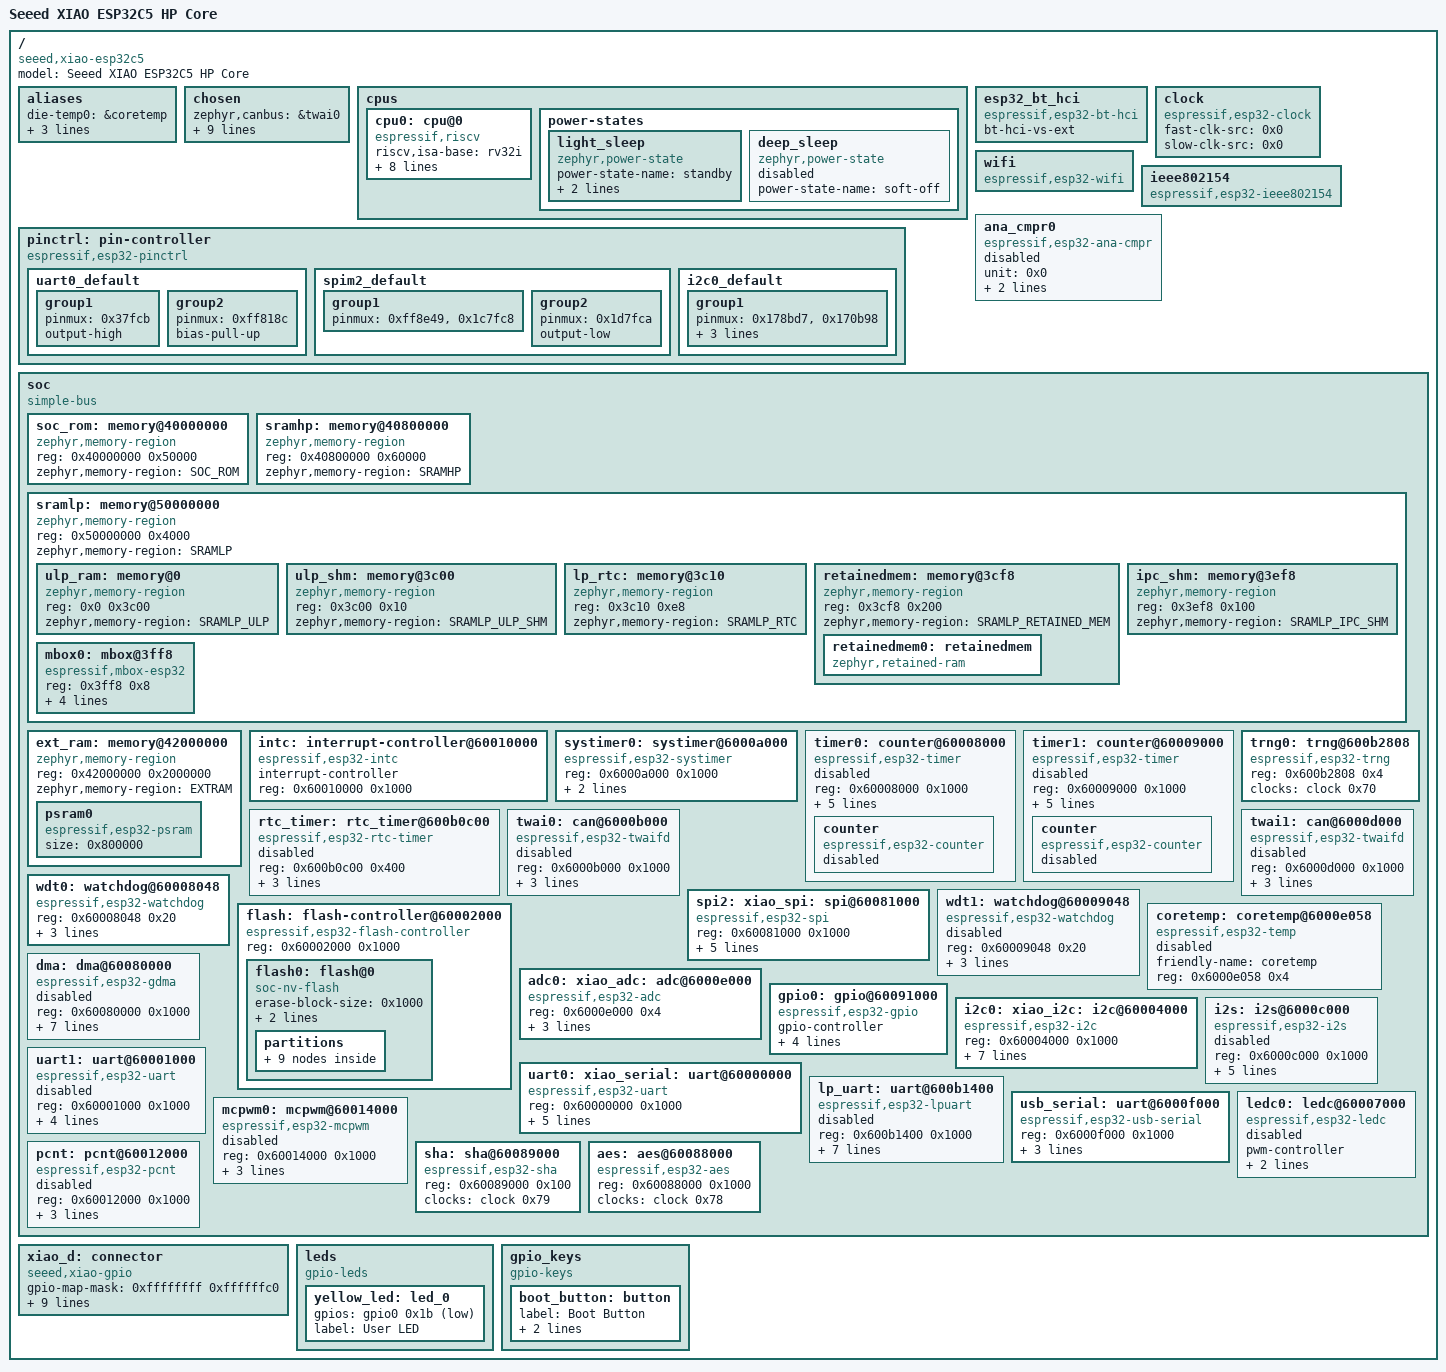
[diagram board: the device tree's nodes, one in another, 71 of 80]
/dts-v1/;

/* node '/' defined in zephyr\dts\riscv\espressif\esp32c5\esp32c5_common.dtsi:16 */
/ {
	#address-cells = < 0x1 >;             /* in zephyr\dts\riscv\espressif\esp32c5\esp32c5_common.dtsi:17 */
	#size-cells = < 0x1 >;                /* in zephyr\dts\riscv\espressif\esp32c5\esp32c5_common.dtsi:18 */
	model = "Seeed XIAO ESP32C5 HP Core"; /* in zephyr\boards\seeed\xiao_esp32c5\xiao_esp32c5_hpcore.dts:15 */
	compatible = "seeed,xiao-esp32c5";    /* in zephyr\boards\seeed\xiao_esp32c5\xiao_esp32c5_hpcore.dts:16 */

	/* node '/aliases' defined in zephyr\dts\riscv\espressif\esp32c5\esp32c5_common.dtsi:20 */
	aliases {
		die-temp0 = &coretemp;             /* in zephyr\dts\riscv\espressif\esp32c5\esp32c5_common.dtsi:21 */
		retainedmemdevice = &retainedmem0; /* in zephyr\dts\riscv\espressif\esp32c5\esp32c5_common.dtsi:22 */
		led0 = &yellow_led;                /* in zephyr\boards\seeed\xiao_esp32c5\xiao_esp32c5_hpcore.dts:37 */
		watchdog0 = &wdt0;                 /* in zephyr\boards\seeed\xiao_esp32c5\xiao_esp32c5_hpcore.dts:38 */
	};

	/* node '/chosen' defined in zephyr\dts\riscv\espressif\esp32c5\esp32c5_common.dtsi:25 */
	chosen {
		zephyr,canbus = &twai0;                   /* in zephyr\dts\riscv\espressif\esp32c5\esp32c5_common.dtsi:26 */
		zephyr,entropy = &trng0;                  /* in zephyr\dts\riscv\espressif\esp32c5\esp32c5_common.dtsi:27 */
		zephyr,flash-controller = &flash;         /* in zephyr\dts\riscv\espressif\esp32c5\esp32c5_common.dtsi:28 */
		zephyr,bt-hci = &esp32_bt_hci;            /* in zephyr\dts\riscv\espressif\esp32c5\esp32c5_common.dtsi:29 */
		zephyr,sram = &sramhp;                    /* in zephyr\boards\seeed\xiao_esp32c5\xiao_esp32c5_hpcore.dts:19 */
		zephyr,console = &usb_serial;             /* in zephyr\boards\seeed\xiao_esp32c5\xiao_esp32c5_hpcore.dts:20 */
		zephyr,shell-uart = &usb_serial;          /* in zephyr\boards\seeed\xiao_esp32c5\xiao_esp32c5_hpcore.dts:21 */
		zephyr,flash = &flash0;                   /* in zephyr\boards\seeed\xiao_esp32c5\xiao_esp32c5_hpcore.dts:22 */
		zephyr,code-partition = &slot0_partition; /* in zephyr\boards\seeed\xiao_esp32c5\xiao_esp32c5_hpcore.dts:23 */
		zephyr,ieee802154 = &ieee802154;          /* in zephyr\boards\seeed\xiao_esp32c5\xiao_esp32c5_hpcore.dts:24 */
	};

	/* node '/cpus' defined in zephyr\dts\riscv\espressif\esp32c5\esp32c5_common.dtsi:32 */
	cpus {
		#address-cells = < 0x1 >; /* in zephyr\dts\riscv\espressif\esp32c5\esp32c5_common.dtsi:33 */
		#size-cells = < 0x0 >;    /* in zephyr\dts\riscv\espressif\esp32c5\esp32c5_common.dtsi:34 */

		/* node '/cpus/cpu@0' defined in zephyr\dts\riscv\espressif\esp32c5\esp32c5_common.dtsi:36 */
		cpu0: cpu@0 {
			device_type = "cpu";                             /* in zephyr\dts\riscv\espressif\esp32c5\esp32c5_common.dtsi:37 */
			compatible = "espressif,riscv",
			             "riscv";                            /* in zephyr\dts\riscv\espressif\esp32c5\esp32c5_common.dtsi:38 */
			riscv,isa-base = "rv32i";                        /* in zephyr\dts\riscv\espressif\esp32c5\esp32c5_common.dtsi:39 */
			riscv,isa-extensions = "i",
			                       "m",
			                       "a",
			                       "c",
			                       "zicsr",
			                       "zifencei";               /* in zephyr\dts\riscv\espressif\esp32c5\esp32c5_common.dtsi:40 */
			reg = < 0x0 >;                                   /* in zephyr\dts\riscv\espressif\esp32c5\esp32c5_common.dtsi:41 */
			cpu-power-states = < &light_sleep &deep_sleep >; /* in zephyr\dts\riscv\espressif\esp32c5\esp32c5_common.dtsi:42 */
			clock-source = < 0x1 >;                          /* in zephyr\dts\riscv\espressif\esp32c5\esp32c5_common.dtsi:43 */
			clock-frequency = < 0xe4e1c00 >;                 /* in zephyr\dts\riscv\espressif\esp32c5\esp32c5_common.dtsi:44 */
			xtal-freq = < 0x2dc6c00 >;                       /* in zephyr\dts\riscv\espressif\esp32c5\esp32c5_common.dtsi:45 */
			d-cache-line-size = < 0x20 >;                    /* in zephyr\dts\riscv\espressif\esp32c5\esp32c5_common.dtsi:46 */
		};

		/* node '/cpus/power-states' defined in zephyr\dts\riscv\espressif\esp32c5\esp32c5_common.dtsi:49 */
		power-states {

			/* node '/cpus/power-states/light_sleep' defined in zephyr\dts\riscv\espressif\esp32c5\esp32c5_common.dtsi:50 */
			light_sleep: light_sleep {
				compatible = "zephyr,power-state"; /* in zephyr\dts\riscv\espressif\esp32c5\esp32c5_common.dtsi:51 */
				power-state-name = "standby";      /* in zephyr\dts\riscv\espressif\esp32c5\esp32c5_common.dtsi:52 */
				min-residency-us = < 0x9c4 >;      /* in zephyr\dts\riscv\espressif\esp32c5\esp32c5_common.dtsi:53 */
				exit-latency-us = < 0x32 >;        /* in zephyr\dts\riscv\espressif\esp32c5\esp32c5_common.dtsi:54 */
				phandle = < 0x1 >;                 /* in zephyr\dts\riscv\espressif\esp32c5\esp32c5_common.dtsi:42 */
			};

			/* node '/cpus/power-states/deep_sleep' defined in zephyr\dts\riscv\espressif\esp32c5\esp32c5_common.dtsi:57 */
			deep_sleep: deep_sleep {
				compatible = "zephyr,power-state"; /* in zephyr\dts\riscv\espressif\esp32c5\esp32c5_common.dtsi:61 */
				power-state-name = "soft-off";     /* in zephyr\dts\riscv\espressif\esp32c5\esp32c5_common.dtsi:62 */
				status = "disabled";               /* in zephyr\dts\riscv\espressif\esp32c5\esp32c5_common.dtsi:63 */
				phandle = < 0x2 >;                 /* in zephyr\dts\riscv\espressif\esp32c5\esp32c5_common.dtsi:42 */
			};
		};
	};

	/* node '/pin-controller' defined in zephyr\dts\riscv\espressif\esp32c5\esp32c5_common.dtsi:68 */
	pinctrl: pin-controller {
		compatible = "espressif,esp32-pinctrl"; /* in zephyr\dts\riscv\espressif\esp32c5\esp32c5_common.dtsi:69 */
		status = "okay";                        /* in zephyr\dts\riscv\espressif\esp32c5\esp32c5_common.dtsi:70 */

		/* node '/pin-controller/uart0_default' defined in zephyr\boards\seeed\xiao_esp32c5\xiao_esp32c5-pinctrl.dtsi:9 */
		uart0_default: uart0_default {
			phandle = < 0xa >; /* in zephyr\boards\seeed\xiao_esp32c5\xiao_esp32c5_hpcore.dts:92 */

			/* node '/pin-controller/uart0_default/group1' defined in zephyr\boards\seeed\xiao_esp32c5\xiao_esp32c5-pinctrl.dtsi:10 */
			group1 {
				pinmux = < 0x37fcb >; /* in zephyr\boards\seeed\xiao_esp32c5\xiao_esp32c5-pinctrl.dtsi:11 */
				output-high;          /* in zephyr\boards\seeed\xiao_esp32c5\xiao_esp32c5-pinctrl.dtsi:12 */
			};

			/* node '/pin-controller/uart0_default/group2' defined in zephyr\boards\seeed\xiao_esp32c5\xiao_esp32c5-pinctrl.dtsi:15 */
			group2 {
				pinmux = < 0xff818c >; /* in zephyr\boards\seeed\xiao_esp32c5\xiao_esp32c5-pinctrl.dtsi:16 */
				bias-pull-up;          /* in zephyr\boards\seeed\xiao_esp32c5\xiao_esp32c5-pinctrl.dtsi:17 */
			};
		};

		/* node '/pin-controller/spim2_default' defined in zephyr\boards\seeed\xiao_esp32c5\xiao_esp32c5-pinctrl.dtsi:21 */
		spim2_default: spim2_default {
			phandle = < 0x6 >; /* in zephyr\boards\seeed\xiao_esp32c5\xiao_esp32c5_hpcore.dts:85 */

			/* node '/pin-controller/spim2_default/group1' defined in zephyr\boards\seeed\xiao_esp32c5\xiao_esp32c5-pinctrl.dtsi:22 */
			group1 {
				pinmux = < 0xff8e49 >,
				         < 0x1c7fc8 >; /* in zephyr\boards\seeed\xiao_esp32c5\xiao_esp32c5-pinctrl.dtsi:23 */
			};

			/* node '/pin-controller/spim2_default/group2' defined in zephyr\boards\seeed\xiao_esp32c5\xiao_esp32c5-pinctrl.dtsi:27 */
			group2 {
				pinmux = < 0x1d7fca >; /* in zephyr\boards\seeed\xiao_esp32c5\xiao_esp32c5-pinctrl.dtsi:28 */
				output-low;            /* in zephyr\boards\seeed\xiao_esp32c5\xiao_esp32c5-pinctrl.dtsi:29 */
			};
		};

		/* node '/pin-controller/i2c0_default' defined in zephyr\boards\seeed\xiao_esp32c5\xiao_esp32c5-pinctrl.dtsi:33 */
		i2c0_default: i2c0_default {
			phandle = < 0x8 >; /* in zephyr\boards\seeed\xiao_esp32c5\xiao_esp32c5_hpcore.dts:77 */

			/* node '/pin-controller/i2c0_default/group1' defined in zephyr\boards\seeed\xiao_esp32c5\xiao_esp32c5-pinctrl.dtsi:34 */
			group1 {
				pinmux = < 0x178bd7 >,
				         < 0x170b98 >; /* in zephyr\boards\seeed\xiao_esp32c5\xiao_esp32c5-pinctrl.dtsi:35 */
				bias-pull-up;          /* in zephyr\boards\seeed\xiao_esp32c5\xiao_esp32c5-pinctrl.dtsi:37 */
				drive-open-drain;      /* in zephyr\boards\seeed\xiao_esp32c5\xiao_esp32c5-pinctrl.dtsi:38 */
				output-high;           /* in zephyr\boards\seeed\xiao_esp32c5\xiao_esp32c5-pinctrl.dtsi:39 */
			};
		};
	};

	/* node '/esp32_bt_hci' defined in zephyr\dts\riscv\espressif\esp32c5\esp32c5_common.dtsi:73 */
	esp32_bt_hci: esp32_bt_hci {
		compatible = "espressif,esp32-bt-hci"; /* in zephyr\dts\riscv\espressif\esp32c5\esp32c5_common.dtsi:74 */
		bt-hci-vs-ext;                         /* in zephyr\dts\riscv\espressif\esp32c5\esp32c5_common.dtsi:75 */
		status = "okay";                       /* in zephyr\boards\seeed\xiao_esp32c5\xiao_esp32c5_hpcore.dts:105 */
	};

	/* node '/clock' defined in zephyr\dts\riscv\espressif\esp32c5\esp32c5_common.dtsi:79 */
	clock: clock {
		compatible = "espressif,esp32-clock"; /* in zephyr\dts\riscv\espressif\esp32c5\esp32c5_common.dtsi:80 */
		fast-clk-src = < 0x0 >;               /* in zephyr\dts\riscv\espressif\esp32c5\esp32c5_common.dtsi:81 */
		slow-clk-src = < 0x0 >;               /* in zephyr\dts\riscv\espressif\esp32c5\esp32c5_common.dtsi:82 */
		#clock-cells = < 0x1 >;               /* in zephyr\dts\riscv\espressif\esp32c5\esp32c5_common.dtsi:83 */
		status = "okay";                      /* in zephyr\dts\riscv\espressif\esp32c5\esp32c5_common.dtsi:84 */
		phandle = < 0x5 >;                    /* in zephyr\dts\riscv\espressif\esp32c5\esp32c5_common.dtsi:222 */
	};

	/* node '/wifi' defined in zephyr\dts\riscv\espressif\esp32c5\esp32c5_common.dtsi:87 */
	wifi: wifi {
		compatible = "espressif,esp32-wifi"; /* in zephyr\dts\riscv\espressif\esp32c5\esp32c5_common.dtsi:88 */
		status = "okay";                     /* in zephyr\boards\seeed\xiao_esp32c5\xiao_esp32c5_hpcore.dts:97 */
	};

	/* node '/ieee802154' defined in zephyr\dts\riscv\espressif\esp32c5\esp32c5_common.dtsi:92 */
	ieee802154: ieee802154 {
		compatible = "espressif,esp32-ieee802154"; /* in zephyr\dts\riscv\espressif\esp32c5\esp32c5_common.dtsi:93 */
		status = "okay";                           /* in zephyr\boards\seeed\xiao_esp32c5\xiao_esp32c5_hpcore.dts:101 */
	};

	/* node '/ana_cmpr0' defined in zephyr\dts\riscv\espressif\esp32c5\esp32c5_common.dtsi:97 */
	ana_cmpr0: ana_cmpr0 {
		compatible = "espressif,esp32-ana-cmpr"; /* in zephyr\dts\riscv\espressif\esp32c5\esp32c5_common.dtsi:98 */
		unit = < 0x0 >;                          /* in zephyr\dts\riscv\espressif\esp32c5\esp32c5_common.dtsi:99 */
		interrupts = < 0x20 0x0 0x0 >;           /* in zephyr\dts\riscv\espressif\esp32c5\esp32c5_common.dtsi:100 */
		interrupt-parent = < &intc >;            /* in zephyr\dts\riscv\espressif\esp32c5\esp32c5_common.dtsi:101 */
		status = "disabled";                     /* in zephyr\dts\riscv\espressif\esp32c5\esp32c5_common.dtsi:102 */
	};

	/* node '/soc' defined in zephyr\dts\riscv\espressif\esp32c5\esp32c5_common.dtsi:105 */
	soc {
		#address-cells = < 0x1 >;  /* in zephyr\dts\riscv\espressif\esp32c5\esp32c5_common.dtsi:106 */
		#size-cells = < 0x1 >;     /* in zephyr\dts\riscv\espressif\esp32c5\esp32c5_common.dtsi:107 */
		compatible = "simple-bus"; /* in zephyr\dts\riscv\espressif\esp32c5\esp32c5_common.dtsi:108 */
		ranges;                    /* in zephyr\dts\riscv\espressif\esp32c5\esp32c5_common.dtsi:109 */

		/* node '/soc/memory@40000000' defined in zephyr\dts\riscv\espressif\esp32c5\esp32c5_common.dtsi:116 */
		soc_rom: memory@40000000 {
			compatible = "zephyr,memory-region"; /* in zephyr\dts\riscv\espressif\esp32c5\esp32c5_common.dtsi:117 */
			reg = < 0x40000000 0x50000 >;        /* in zephyr\dts\riscv\espressif\esp32c5\esp32c5_common.dtsi:118 */
			zephyr,memory-region = "SOC_ROM";    /* in zephyr\dts\riscv\espressif\esp32c5\esp32c5_common.dtsi:119 */
		};

		/* node '/soc/memory@40800000' defined in zephyr\dts\riscv\espressif\esp32c5\esp32c5_common.dtsi:122 */
		sramhp: memory@40800000 {
			compatible = "zephyr,memory-region",
			             "mmio-sram";            /* in zephyr\dts\riscv\espressif\esp32c5\esp32c5_common.dtsi:123 */
			reg = < 0x40800000 0x60000 >;        /* in zephyr\dts\riscv\espressif\esp32c5\esp32c5_common.dtsi:124 */
			zephyr,memory-region = "SRAMHP";     /* in zephyr\dts\riscv\espressif\esp32c5\esp32c5_common.dtsi:125 */
		};

		/* node '/soc/memory@50000000' defined in zephyr\dts\riscv\espressif\esp32c5\esp32c5_common.dtsi:128 */
		sramlp: memory@50000000 {
			#address-cells = < 0x1 >;            /* in zephyr\dts\riscv\espressif\esp32c5\esp32c5_common.dtsi:129 */
			#size-cells = < 0x1 >;               /* in zephyr\dts\riscv\espressif\esp32c5\esp32c5_common.dtsi:130 */
			compatible = "zephyr,memory-region",
			             "mmio-sram";            /* in zephyr\dts\riscv\espressif\esp32c5\esp32c5_common.dtsi:131 */
			reg = < 0x50000000 0x4000 >;         /* in zephyr\dts\riscv\espressif\esp32c5\esp32c5_common.dtsi:132 */
			zephyr,memory-region = "SRAMLP";     /* in zephyr\dts\riscv\espressif\esp32c5\esp32c5_common.dtsi:133 */
			ranges = < 0x0 0x50000000 0x4000 >;  /* in zephyr\dts\riscv\espressif\esp32c5\esp32c5_common.dtsi:134 */

			/* node '/soc/memory@50000000/memory@0' defined in zephyr\dts\riscv\espressif\esp32c5\esp32c5_common.dtsi:136 */
			ulp_ram: memory@0 {
				compatible = "zephyr,memory-region",
				             "mmio-sram";            /* in zephyr\dts\riscv\espressif\esp32c5\esp32c5_common.dtsi:137 */
				reg = < 0x0 0x3c00 >;                /* in zephyr\dts\riscv\espressif\esp32c5\esp32c5_common.dtsi:138 */
				zephyr,memory-region = "SRAMLP_ULP"; /* in zephyr\dts\riscv\espressif\esp32c5\esp32c5_common.dtsi:139 */
			};

			/* node '/soc/memory@50000000/memory@3c00' defined in zephyr\dts\riscv\espressif\esp32c5\esp32c5_common.dtsi:142 */
			ulp_shm: memory@3c00 {
				compatible = "zephyr,memory-region",
				             "mmio-sram";                /* in zephyr\dts\riscv\espressif\esp32c5\esp32c5_common.dtsi:143 */
				reg = < 0x3c00 0x10 >;                   /* in zephyr\dts\riscv\espressif\esp32c5\esp32c5_common.dtsi:144 */
				zephyr,memory-region = "SRAMLP_ULP_SHM"; /* in zephyr\dts\riscv\espressif\esp32c5\esp32c5_common.dtsi:145 */
			};

			/* node '/soc/memory@50000000/memory@3c10' defined in zephyr\dts\riscv\espressif\esp32c5\esp32c5_common.dtsi:148 */
			lp_rtc: memory@3c10 {
				compatible = "zephyr,memory-region",
				             "mmio-sram";            /* in zephyr\dts\riscv\espressif\esp32c5\esp32c5_common.dtsi:149 */
				reg = < 0x3c10 0xe8 >;               /* in zephyr\dts\riscv\espressif\esp32c5\esp32c5_common.dtsi:150 */
				zephyr,memory-region = "SRAMLP_RTC"; /* in zephyr\dts\riscv\espressif\esp32c5\esp32c5_common.dtsi:151 */
			};

			/* node '/soc/memory@50000000/memory@3cf8' defined in zephyr\dts\riscv\espressif\esp32c5\esp32c5_common.dtsi:154 */
			retainedmem: memory@3cf8 {
				compatible = "zephyr,memory-region",
				             "mmio-sram";                     /* in zephyr\dts\riscv\espressif\esp32c5\esp32c5_common.dtsi:155 */
				reg = < 0x3cf8 0x200 >;                       /* in zephyr\dts\riscv\espressif\esp32c5\esp32c5_common.dtsi:156 */
				ranges = < 0x0 0x3cf8 0x200 >;                /* in zephyr\dts\riscv\espressif\esp32c5\esp32c5_common.dtsi:157 */
				zephyr,memory-region = "SRAMLP_RETAINED_MEM"; /* in zephyr\dts\riscv\espressif\esp32c5\esp32c5_common.dtsi:158 */
				status = "okay";                              /* in zephyr\dts\riscv\espressif\esp32c5\esp32c5_common.dtsi:159 */
				#address-cells = < 0x1 >;                     /* in zephyr\dts\riscv\espressif\esp32c5\esp32c5_common.dtsi:160 */
				#size-cells = < 0x1 >;                        /* in zephyr\dts\riscv\espressif\esp32c5\esp32c5_common.dtsi:161 */

				/* node '/soc/memory@50000000/memory@3cf8/retainedmem' defined in zephyr\dts\riscv\espressif\esp32c5\esp32c5_common.dtsi:163 */
				retainedmem0: retainedmem {
					compatible = "zephyr,retained-ram"; /* in zephyr\dts\riscv\espressif\esp32c5\esp32c5_common.dtsi:164 */
					status = "okay";                    /* in zephyr\dts\riscv\espressif\esp32c5\esp32c5_common.dtsi:165 */
					ranges;                             /* in zephyr\dts\riscv\espressif\esp32c5\esp32c5_common.dtsi:166 */
					#address-cells = < 0x1 >;           /* in zephyr\dts\riscv\espressif\esp32c5\esp32c5_common.dtsi:167 */
					#size-cells = < 0x1 >;              /* in zephyr\dts\riscv\espressif\esp32c5\esp32c5_common.dtsi:168 */
				};
			};

			/* node '/soc/memory@50000000/memory@3ef8' defined in zephyr\dts\riscv\espressif\esp32c5\esp32c5_common.dtsi:172 */
			ipc_shm: memory@3ef8 {
				compatible = "zephyr,memory-region",
				             "mmio-sram";                /* in zephyr\dts\riscv\espressif\esp32c5\esp32c5_common.dtsi:173 */
				reg = < 0x3ef8 0x100 >;                  /* in zephyr\dts\riscv\espressif\esp32c5\esp32c5_common.dtsi:174 */
				zephyr,memory-region = "SRAMLP_IPC_SHM"; /* in zephyr\dts\riscv\espressif\esp32c5\esp32c5_common.dtsi:175 */
				phandle = < 0x4 >;                       /* in zephyr\dts\riscv\espressif\esp32c5\esp32c5_common.dtsi:182 */
			};

			/* node '/soc/memory@50000000/mbox@3ff8' defined in zephyr\dts\riscv\espressif\esp32c5\esp32c5_common.dtsi:178 */
			mbox0: mbox@3ff8 {
				compatible = "espressif,mbox-esp32"; /* in zephyr\dts\riscv\espressif\esp32c5\esp32c5_common.dtsi:179 */
				reg = < 0x3ff8 0x8 >;                /* in zephyr\dts\riscv\espressif\esp32c5\esp32c5_common.dtsi:180 */
				status = "okay";                     /* in zephyr\dts\riscv\espressif\esp32c5\esp32c5_common.dtsi:181 */
				shared-memory = < &ipc_shm >;        /* in zephyr\dts\riscv\espressif\esp32c5\esp32c5_common.dtsi:182 */
				shared-memory-size = < 0x100 >;      /* in zephyr\dts\riscv\espressif\esp32c5\esp32c5_common.dtsi:183 */
				interrupts = < 0xd 0x0 0x0 >,
				             < 0x5 0x0 0x0 >;        /* in zephyr\dts\riscv\espressif\esp32c5\esp32c5_common.dtsi:184 */
				interrupt-parent = < &intc >;        /* in zephyr\dts\riscv\espressif\esp32c5\esp32c5_common.dtsi:186 */
				#mbox-cells = < 0x1 >;               /* in zephyr\dts\riscv\espressif\esp32c5\esp32c5_common.dtsi:187 */
			};
		};

		/* node '/soc/memory@42000000' defined in zephyr\dts\riscv\espressif\esp32c5\esp32c5_common.dtsi:191 */
		ext_ram: memory@42000000 {
			compatible = "zephyr,memory-region"; /* in zephyr\dts\riscv\espressif\esp32c5\esp32c5_common.dtsi:192 */
			reg = < 0x42000000 0x2000000 >;      /* in zephyr\dts\riscv\espressif\esp32c5\esp32c5_common.dtsi:193 */
			zephyr,memory-region = "EXTRAM";     /* in zephyr\dts\riscv\espressif\esp32c5\esp32c5_common.dtsi:194 */

			/* node '/soc/memory@42000000/psram0' defined in zephyr\dts\riscv\espressif\esp32c5\esp32c5_common.dtsi:196 */
			psram0: psram0 {
				compatible = "espressif,esp32-psram"; /* in zephyr\dts\riscv\espressif\esp32c5\esp32c5_common.dtsi:197 */
				size = < 0x800000 >;                  /* in zephyr\dts\riscv\espressif\esp32c5\esp32c5_wroom_n8r8.dtsi:17 */
			};
		};

		/* node '/soc/interrupt-controller@60010000' defined in zephyr\dts\riscv\espressif\esp32c5\esp32c5_common.dtsi:202 */
		intc: interrupt-controller@60010000 {
			compatible = "espressif,esp32-intc"; /* in zephyr\dts\riscv\espressif\esp32c5\esp32c5_common.dtsi:203 */
			#address-cells = < 0x0 >;            /* in zephyr\dts\riscv\espressif\esp32c5\esp32c5_common.dtsi:204 */
			#interrupt-cells = < 0x3 >;          /* in zephyr\dts\riscv\espressif\esp32c5\esp32c5_common.dtsi:205 */
			interrupt-controller;                /* in zephyr\dts\riscv\espressif\esp32c5\esp32c5_common.dtsi:206 */
			reg = < 0x60010000 0x1000 >;         /* in zephyr\dts\riscv\espressif\esp32c5\esp32c5_common.dtsi:207 */
			status = "okay";                     /* in zephyr\dts\riscv\espressif\esp32c5\esp32c5_common.dtsi:208 */
			phandle = < 0x3 >;                   /* in zephyr\dts\riscv\espressif\esp32c5\esp32c5_common.dtsi:101 */
		};

		/* node '/soc/systimer@6000a000' defined in zephyr\dts\riscv\espressif\esp32c5\esp32c5_common.dtsi:211 */
		systimer0: systimer@6000a000 {
			compatible = "espressif,esp32-systimer"; /* in zephyr\dts\riscv\espressif\esp32c5\esp32c5_common.dtsi:212 */
			reg = < 0x6000a000 0x1000 >;             /* in zephyr\dts\riscv\espressif\esp32c5\esp32c5_common.dtsi:213 */
			interrupts = < 0x3d 0x0 0x0 >;           /* in zephyr\dts\riscv\espressif\esp32c5\esp32c5_common.dtsi:214 */
			interrupt-parent = < &intc >;            /* in zephyr\dts\riscv\espressif\esp32c5\esp32c5_common.dtsi:215 */
			status = "okay";                         /* in zephyr\dts\riscv\espressif\esp32c5\esp32c5_common.dtsi:216 */
		};

		/* node '/soc/counter@60008000' defined in zephyr\dts\riscv\espressif\esp32c5\esp32c5_common.dtsi:219 */
		timer0: counter@60008000 {
			compatible = "espressif,esp32-timer"; /* in zephyr\dts\riscv\espressif\esp32c5\esp32c5_common.dtsi:220 */
			reg = < 0x60008000 0x1000 >;          /* in zephyr\dts\riscv\espressif\esp32c5\esp32c5_common.dtsi:221 */
			clocks = < &clock 0x0 >;              /* in zephyr\dts\riscv\espressif\esp32c5\esp32c5_common.dtsi:222 */
			group = < 0x0 >;                      /* in zephyr\dts\riscv\espressif\esp32c5\esp32c5_common.dtsi:223 */
			index = < 0x0 >;                      /* in zephyr\dts\riscv\espressif\esp32c5\esp32c5_common.dtsi:224 */
			interrupts = < 0x39 0x0 0x0 >;        /* in zephyr\dts\riscv\espressif\esp32c5\esp32c5_common.dtsi:225 */
			interrupt-parent = < &intc >;         /* in zephyr\dts\riscv\espressif\esp32c5\esp32c5_common.dtsi:226 */
			status = "disabled";                  /* in zephyr\dts\riscv\espressif\esp32c5\esp32c5_common.dtsi:227 */

			/* node '/soc/counter@60008000/counter' defined in zephyr\dts\riscv\espressif\esp32c5\esp32c5_common.dtsi:229 */
			counter {
				compatible = "espressif,esp32-counter"; /* in zephyr\dts\riscv\espressif\esp32c5\esp32c5_common.dtsi:230 */
				status = "disabled";                    /* in zephyr\dts\riscv\espressif\esp32c5\esp32c5_common.dtsi:231 */
			};
		};

		/* node '/soc/counter@60009000' defined in zephyr\dts\riscv\espressif\esp32c5\esp32c5_common.dtsi:235 */
		timer1: counter@60009000 {
			compatible = "espressif,esp32-timer"; /* in zephyr\dts\riscv\espressif\esp32c5\esp32c5_common.dtsi:236 */
			reg = < 0x60009000 0x1000 >;          /* in zephyr\dts\riscv\espressif\esp32c5\esp32c5_common.dtsi:237 */
			clocks = < &clock 0x1 >;              /* in zephyr\dts\riscv\espressif\esp32c5\esp32c5_common.dtsi:238 */
			group = < 0x1 >;                      /* in zephyr\dts\riscv\espressif\esp32c5\esp32c5_common.dtsi:239 */
			index = < 0x0 >;                      /* in zephyr\dts\riscv\espressif\esp32c5\esp32c5_common.dtsi:240 */
			interrupts = < 0x3b 0x0 0x0 >;        /* in zephyr\dts\riscv\espressif\esp32c5\esp32c5_common.dtsi:241 */
			interrupt-parent = < &intc >;         /* in zephyr\dts\riscv\espressif\esp32c5\esp32c5_common.dtsi:242 */
			status = "disabled";                  /* in zephyr\dts\riscv\espressif\esp32c5\esp32c5_common.dtsi:243 */

			/* node '/soc/counter@60009000/counter' defined in zephyr\dts\riscv\espressif\esp32c5\esp32c5_common.dtsi:245 */
			counter {
				compatible = "espressif,esp32-counter"; /* in zephyr\dts\riscv\espressif\esp32c5\esp32c5_common.dtsi:246 */
				status = "disabled";                    /* in zephyr\dts\riscv\espressif\esp32c5\esp32c5_common.dtsi:247 */
			};
		};

		/* node '/soc/rtc_timer@600b0c00' defined in zephyr\dts\riscv\espressif\esp32c5\esp32c5_common.dtsi:251 */
		rtc_timer: rtc_timer@600b0c00 {
			compatible = "espressif,esp32-rtc-timer"; /* in zephyr\dts\riscv\espressif\esp32c5\esp32c5_common.dtsi:252 */
			reg = < 0x600b0c00 0x400 >;               /* in zephyr\dts\riscv\espressif\esp32c5\esp32c5_common.dtsi:253 */
			clocks = < &clock 0xd >;                  /* in zephyr\dts\riscv\espressif\esp32c5\esp32c5_common.dtsi:254 */
			interrupts = < 0xf 0x0 0x0 >;             /* in zephyr\dts\riscv\espressif\esp32c5\esp32c5_common.dtsi:255 */
			interrupt-parent = < &intc >;             /* in zephyr\dts\riscv\espressif\esp32c5\esp32c5_common.dtsi:256 */
			status = "disabled";                      /* in zephyr\dts\riscv\espressif\esp32c5\esp32c5_common.dtsi:257 */
		};

		/* node '/soc/trng@600b2808' defined in zephyr\dts\riscv\espressif\esp32c5\esp32c5_common.dtsi:260 */
		trng0: trng@600b2808 {
			compatible = "espressif,esp32-trng"; /* in zephyr\dts\riscv\espressif\esp32c5\esp32c5_common.dtsi:261 */
			reg = < 0x600b2808 0x4 >;            /* in zephyr\dts\riscv\espressif\esp32c5\esp32c5_common.dtsi:262 */
			clocks = < &clock 0x70 >;            /* in zephyr\dts\riscv\espressif\esp32c5\esp32c5_common.dtsi:263 */
			status = "okay";                     /* in zephyr\boards\seeed\xiao_esp32c5\xiao_esp32c5_hpcore.dts:53 */
		};

		/* node '/soc/can@6000b000' defined in zephyr\dts\riscv\espressif\esp32c5\esp32c5_common.dtsi:267 */
		twai0: can@6000b000 {
			compatible = "espressif,esp32-twaifd"; /* in zephyr\dts\riscv\espressif\esp32c5\esp32c5_common.dtsi:268 */
			reg = < 0x6000b000 0x1000 >;           /* in zephyr\dts\riscv\espressif\esp32c5\esp32c5_common.dtsi:269 */
			interrupts = < 0x32 0x0 0x0 >;         /* in zephyr\dts\riscv\espressif\esp32c5\esp32c5_common.dtsi:270 */
			interrupt-parent = < &intc >;          /* in zephyr\dts\riscv\espressif\esp32c5\esp32c5_common.dtsi:271 */
			clocks = < &clock 0x6e >;              /* in zephyr\dts\riscv\espressif\esp32c5\esp32c5_common.dtsi:272 */
			status = "disabled";                   /* in zephyr\dts\riscv\espressif\esp32c5\esp32c5_common.dtsi:273 */
		};

		/* node '/soc/can@6000d000' defined in zephyr\dts\riscv\espressif\esp32c5\esp32c5_common.dtsi:276 */
		twai1: can@6000d000 {
			compatible = "espressif,esp32-twaifd"; /* in zephyr\dts\riscv\espressif\esp32c5\esp32c5_common.dtsi:277 */
			reg = < 0x6000d000 0x1000 >;           /* in zephyr\dts\riscv\espressif\esp32c5\esp32c5_common.dtsi:278 */
			interrupts = < 0x34 0x0 0x0 >;         /* in zephyr\dts\riscv\espressif\esp32c5\esp32c5_common.dtsi:279 */
			interrupt-parent = < &intc >;          /* in zephyr\dts\riscv\espressif\esp32c5\esp32c5_common.dtsi:280 */
			clocks = < &clock 0x6f >;              /* in zephyr\dts\riscv\espressif\esp32c5\esp32c5_common.dtsi:281 */
			status = "disabled";                   /* in zephyr\dts\riscv\espressif\esp32c5\esp32c5_common.dtsi:282 */
		};

		/* node '/soc/spi@60081000' defined in zephyr\dts\riscv\espressif\esp32c5\esp32c5_common.dtsi:285 */
		spi2: xiao_spi: spi@60081000 {
			compatible = "espressif,esp32-spi"; /* in zephyr\dts\riscv\espressif\esp32c5\esp32c5_common.dtsi:286 */
			reg = < 0x60081000 0x1000 >;        /* in zephyr\dts\riscv\espressif\esp32c5\esp32c5_common.dtsi:287 */
			interrupts = < 0x4d 0x0 0x0 >;      /* in zephyr\dts\riscv\espressif\esp32c5\esp32c5_common.dtsi:288 */
			interrupt-parent = < &intc >;       /* in zephyr\dts\riscv\espressif\esp32c5\esp32c5_common.dtsi:289 */
			clocks = < &clock 0x6d >;           /* in zephyr\dts\riscv\espressif\esp32c5\esp32c5_common.dtsi:290 */
			dma-host = < 0x0 >;                 /* in zephyr\dts\riscv\espressif\esp32c5\esp32c5_common.dtsi:291 */
			#address-cells = < 0x1 >;           /* in zephyr\boards\seeed\xiao_esp32c5\xiao_esp32c5_hpcore.dts:82 */
			#size-cells = < 0x0 >;              /* in zephyr\boards\seeed\xiao_esp32c5\xiao_esp32c5_hpcore.dts:83 */
			status = "okay";                    /* in zephyr\boards\seeed\xiao_esp32c5\xiao_esp32c5_hpcore.dts:84 */
			pinctrl-0 = < &spim2_default >;     /* in zephyr\boards\seeed\xiao_esp32c5\xiao_esp32c5_hpcore.dts:85 */
			pinctrl-names = "default";          /* in zephyr\boards\seeed\xiao_esp32c5\xiao_esp32c5_hpcore.dts:86 */
		};

		/* node '/soc/watchdog@60008048' defined in zephyr\dts\riscv\espressif\esp32c5\esp32c5_common.dtsi:295 */
		wdt0: watchdog@60008048 {
			compatible = "espressif,esp32-watchdog"; /* in zephyr\dts\riscv\espressif\esp32c5\esp32c5_common.dtsi:296 */
			reg = < 0x60008048 0x20 >;               /* in zephyr\dts\riscv\espressif\esp32c5\esp32c5_common.dtsi:297 */
			interrupts = < 0x3a 0x0 0x0 >;           /* in zephyr\dts\riscv\espressif\esp32c5\esp32c5_common.dtsi:298 */
			interrupt-parent = < &intc >;            /* in zephyr\dts\riscv\espressif\esp32c5\esp32c5_common.dtsi:299 */
			clocks = < &clock 0x0 >;                 /* in zephyr\dts\riscv\espressif\esp32c5\esp32c5_common.dtsi:300 */
			status = "okay";                         /* in zephyr\boards\seeed\xiao_esp32c5\xiao_esp32c5_hpcore.dts:61 */
		};

		/* node '/soc/watchdog@60009048' defined in zephyr\dts\riscv\espressif\esp32c5\esp32c5_common.dtsi:304 */
		wdt1: watchdog@60009048 {
			compatible = "espressif,esp32-watchdog"; /* in zephyr\dts\riscv\espressif\esp32c5\esp32c5_common.dtsi:305 */
			reg = < 0x60009048 0x20 >;               /* in zephyr\dts\riscv\espressif\esp32c5\esp32c5_common.dtsi:306 */
			interrupts = < 0x3c 0x0 0x0 >;           /* in zephyr\dts\riscv\espressif\esp32c5\esp32c5_common.dtsi:307 */
			interrupt-parent = < &intc >;            /* in zephyr\dts\riscv\espressif\esp32c5\esp32c5_common.dtsi:308 */
			clocks = < &clock 0x1 >;                 /* in zephyr\dts\riscv\espressif\esp32c5\esp32c5_common.dtsi:309 */
			status = "disabled";                     /* in zephyr\dts\riscv\espressif\esp32c5\esp32c5_common.dtsi:310 */
		};

		/* node '/soc/flash-controller@60002000' defined in zephyr\dts\riscv\espressif\esp32c5\esp32c5_common.dtsi:313 */
		flash: flash-controller@60002000 {
			compatible = "espressif,esp32-flash-controller"; /* in zephyr\dts\riscv\espressif\esp32c5\esp32c5_common.dtsi:314 */
			reg = < 0x60002000 0x1000 >;                     /* in zephyr\dts\riscv\espressif\esp32c5\esp32c5_common.dtsi:315 */
			#address-cells = < 0x1 >;                        /* in zephyr\dts\riscv\espressif\esp32c5\esp32c5_common.dtsi:317 */
			#size-cells = < 0x1 >;                           /* in zephyr\dts\riscv\espressif\esp32c5\esp32c5_common.dtsi:318 */
			ranges;                                          /* in zephyr\dts\riscv\espressif\esp32c5\esp32c5_common.dtsi:319 */

			/* node '/soc/flash-controller@60002000/flash@0' defined in zephyr\dts\riscv\espressif\esp32c5\esp32c5_common.dtsi:321 */
			flash0: flash@0 {
				compatible = "soc-nv-flash";   /* in zephyr\dts\riscv\espressif\esp32c5\esp32c5_common.dtsi:322 */
				erase-block-size = < 0x1000 >; /* in zephyr\dts\riscv\espressif\esp32c5\esp32c5_common.dtsi:323 */
				write-block-size = < 0x4 >;    /* in zephyr\dts\riscv\espressif\esp32c5\esp32c5_common.dtsi:324 */
				#address-cells = < 0x1 >;      /* in zephyr\dts\riscv\espressif\esp32c5\esp32c5_common.dtsi:325 */
				#size-cells = < 0x1 >;         /* in zephyr\dts\riscv\espressif\esp32c5\esp32c5_common.dtsi:326 */
				reg = < 0x0 0x800000 >;        /* in zephyr\dts\riscv\espressif\esp32c5\esp32c5_wroom_n8r8.dtsi:11 */
				ranges = < 0x0 0x0 0x800000 >; /* in zephyr\dts\riscv\espressif\esp32c5\esp32c5_wroom_n8r8.dtsi:12 */

				/* node '/soc/flash-controller@60002000/flash@0/partitions' defined in zephyr\dts\vendor\espressif\partitions_0x2000_default_8M.dtsi:11 */
				partitions {
					ranges;                   /* in zephyr\dts\vendor\espressif\partitions_0x2000_default_8M.dtsi:12 */
					#address-cells = < 0x1 >; /* in zephyr\dts\vendor\espressif\partitions_0x2000_default_8M.dtsi:13 */
					#size-cells = < 0x1 >;    /* in zephyr\dts\vendor\espressif\partitions_0x2000_default_8M.dtsi:14 */

					/* node '/soc/flash-controller@60002000/flash@0/partitions/partition@2000' defined in zephyr\dts\vendor\espressif\partitions_0x2000_default_8M.dtsi:16 */
					boot_partition: partition@2000 {
						compatible = "zephyr,mapped-partition"; /* in zephyr\dts\vendor\espressif\partitions_0x2000_default_8M.dtsi:17 */
						label = "mcuboot";                      /* in zephyr\dts\vendor\espressif\partitions_0x2000_default_8M.dtsi:18 */
						reg = < 0x2000 0xe000 >;                /* in zephyr\dts\vendor\espressif\partitions_0x2000_default_8M.dtsi:19 */
					};

					/* node '/soc/flash-controller@60002000/flash@0/partitions/partition@10000' defined in zephyr\dts\vendor\espressif\partitions_0x2000_default_8M.dtsi:22 */
					sys_partition: partition@10000 {
						compatible = "zephyr,mapped-partition"; /* in zephyr\dts\vendor\espressif\partitions_0x2000_default_8M.dtsi:23 */
						label = "sys";                          /* in zephyr\dts\vendor\espressif\partitions_0x2000_default_8M.dtsi:24 */
						reg = < 0x10000 0x10000 >;              /* in zephyr\dts\vendor\espressif\partitions_0x2000_default_8M.dtsi:25 */
					};

					/* node '/soc/flash-controller@60002000/flash@0/partitions/partition@20000' defined in zephyr\dts\vendor\espressif\partitions_0x2000_default_8M.dtsi:28 */
					slot0_partition: partition@20000 {
						compatible = "zephyr,mapped-partition"; /* in zephyr\dts\vendor\espressif\partitions_0x2000_default_8M.dtsi:29 */
						label = "image-0";                      /* in zephyr\dts\vendor\espressif\partitions_0x2000_default_8M.dtsi:30 */
						reg = < 0x20000 0x3c0000 >;             /* in zephyr\dts\vendor\espressif\partitions_0x2000_default_8M.dtsi:31 */
					};

					/* node '/soc/flash-controller@60002000/flash@0/partitions/partition@3e0000' defined in zephyr\dts\vendor\espressif\partitions_0x2000_default_8M.dtsi:34 */
					slot1_partition: partition@3e0000 {
						compatible = "zephyr,mapped-partition"; /* in zephyr\dts\vendor\espressif\partitions_0x2000_default_8M.dtsi:35 */
						label = "image-1";                      /* in zephyr\dts\vendor\espressif\partitions_0x2000_default_8M.dtsi:36 */
						reg = < 0x3e0000 0x3c0000 >;            /* in zephyr\dts\vendor\espressif\partitions_0x2000_default_8M.dtsi:37 */
					};

					/* node '/soc/flash-controller@60002000/flash@0/partitions/partition@7a0000' defined in zephyr\dts\vendor\espressif\partitions_0x2000_default_8M.dtsi:40 */
					slot0_lpcore_partition: partition@7a0000 {
						compatible = "zephyr,mapped-partition"; /* in zephyr\dts\vendor\espressif\partitions_0x2000_default_8M.dtsi:41 */
						label = "image-0-lpcore";               /* in zephyr\dts\vendor\espressif\partitions_0x2000_default_8M.dtsi:42 */
						reg = < 0x7a0000 0x8000 >;              /* in zephyr\dts\vendor\espressif\partitions_0x2000_default_8M.dtsi:43 */
					};

					/* node '/soc/flash-controller@60002000/flash@0/partitions/partition@7a8000' defined in zephyr\dts\vendor\espressif\partitions_0x2000_default_8M.dtsi:46 */
					slot1_lpcore_partition: partition@7a8000 {
						compatible = "zephyr,mapped-partition"; /* in zephyr\dts\vendor\espressif\partitions_0x2000_default_8M.dtsi:47 */
						label = "image-1-lpcore";               /* in zephyr\dts\vendor\espressif\partitions_0x2000_default_8M.dtsi:48 */
						reg = < 0x7a8000 0x8000 >;              /* in zephyr\dts\vendor\espressif\partitions_0x2000_default_8M.dtsi:49 */
					};

					/* node '/soc/flash-controller@60002000/flash@0/partitions/partition@7b0000' defined in zephyr\dts\vendor\espressif\partitions_0x2000_default_8M.dtsi:52 */
					storage_partition: partition@7b0000 {
						compatible = "zephyr,mapped-partition"; /* in zephyr\dts\vendor\espressif\partitions_0x2000_default_8M.dtsi:53 */
						label = "storage";                      /* in zephyr\dts\vendor\espressif\partitions_0x2000_default_8M.dtsi:54 */
						reg = < 0x7b0000 0x30000 >;             /* in zephyr\dts\vendor\espressif\partitions_0x2000_default_8M.dtsi:55 */
					};

					/* node '/soc/flash-controller@60002000/flash@0/partitions/partition@7e0000' defined in zephyr\dts\vendor\espressif\partitions_0x2000_default_8M.dtsi:58 */
					scratch_partition: partition@7e0000 {
						compatible = "zephyr,mapped-partition"; /* in zephyr\dts\vendor\espressif\partitions_0x2000_default_8M.dtsi:59 */
						label = "image-scratch";                /* in zephyr\dts\vendor\espressif\partitions_0x2000_default_8M.dtsi:60 */
						reg = < 0x7e0000 0x1f000 >;             /* in zephyr\dts\vendor\espressif\partitions_0x2000_default_8M.dtsi:61 */
					};

					/* node '/soc/flash-controller@60002000/flash@0/partitions/partition@7ff000' defined in zephyr\dts\vendor\espressif\partitions_0x2000_default_8M.dtsi:64 */
					coredump_partition: partition@7ff000 {
						compatible = "zephyr,mapped-partition"; /* in zephyr\dts\vendor\espressif\partitions_0x2000_default_8M.dtsi:65 */
						label = "coredump";                     /* in zephyr\dts\vendor\espressif\partitions_0x2000_default_8M.dtsi:66 */
						reg = < 0x7ff000 0x1000 >;              /* in zephyr\dts\vendor\espressif\partitions_0x2000_default_8M.dtsi:67 */
					};
				};
			};
		};

		/* node '/soc/coretemp@6000e058' defined in zephyr\dts\riscv\espressif\esp32c5\esp32c5_common.dtsi:331 */
		coretemp: coretemp@6000e058 {
			compatible = "espressif,esp32-temp"; /* in zephyr\dts\riscv\espressif\esp32c5\esp32c5_common.dtsi:332 */
			friendly-name = "coretemp";          /* in zephyr\dts\riscv\espressif\esp32c5\esp32c5_common.dtsi:333 */
			reg = < 0x6000e058 0x4 >;            /* in zephyr\dts\riscv\espressif\esp32c5\esp32c5_common.dtsi:334 */
			status = "disabled";                 /* in zephyr\dts\riscv\espressif\esp32c5\esp32c5_common.dtsi:335 */
		};

		/* node '/soc/adc@6000e000' defined in zephyr\dts\riscv\espressif\esp32c5\esp32c5_common.dtsi:338 */
		adc0: xiao_adc: adc@6000e000 {
			compatible = "espressif,esp32-adc"; /* in zephyr\dts\riscv\espressif\esp32c5\esp32c5_common.dtsi:339 */
			reg = < 0x6000e000 0x4 >;           /* in zephyr\dts\riscv\espressif\esp32c5\esp32c5_common.dtsi:340 */
			clocks = < &clock 0x76 >;           /* in zephyr\dts\riscv\espressif\esp32c5\esp32c5_common.dtsi:341 */
			unit = < 0x1 >;                     /* in zephyr\dts\riscv\espressif\esp32c5\esp32c5_common.dtsi:342 */
			channel-count = < 0x6 >;            /* in zephyr\dts\riscv\espressif\esp32c5\esp32c5_common.dtsi:343 */
			#io-channel-cells = < 0x1 >;        /* in zephyr\dts\riscv\espressif\esp32c5\esp32c5_common.dtsi:344 */
			status = "okay";                    /* in zephyr\boards\seeed\xiao_esp32c5\xiao_esp32c5_hpcore.dts:69 */
		};

		/* node '/soc/dma@60080000' defined in zephyr\dts\riscv\espressif\esp32c5\esp32c5_common.dtsi:348 */
		dma: dma@60080000 {
			compatible = "espressif,esp32-gdma"; /* in zephyr\dts\riscv\espressif\esp32c5\esp32c5_common.dtsi:349 */
			reg = < 0x60080000 0x1000 >;         /* in zephyr\dts\riscv\espressif\esp32c5\esp32c5_common.dtsi:350 */
			#dma-cells = < 0x1 >;                /* in zephyr\dts\riscv\espressif\esp32c5\esp32c5_common.dtsi:351 */
			interrupts = < 0x47 0x0 0x0 >,
			             < 0x4a 0x0 0x0 >,
			             < 0x48 0x0 0x0 >,
			             < 0x4b 0x0 0x0 >,
			             < 0x49 0x0 0x0 >,
			             < 0x4c 0x0 0x0 >;       /* in zephyr\dts\riscv\espressif\esp32c5\esp32c5_common.dtsi:352 */
			interrupt-parent = < &intc >;        /* in zephyr\dts\riscv\espressif\esp32c5\esp32c5_common.dtsi:358 */
			clocks = < &clock 0x71 >;            /* in zephyr\dts\riscv\espressif\esp32c5\esp32c5_common.dtsi:359 */
			dma-channels = < 0x6 >;              /* in zephyr\dts\riscv\espressif\esp32c5\esp32c5_common.dtsi:360 */
			dma-buf-addr-alignment = < 0x4 >;    /* in zephyr\dts\riscv\espressif\esp32c5\esp32c5_common.dtsi:361 */
			status = "disabled";                 /* in zephyr\dts\riscv\espressif\esp32c5\esp32c5_common.dtsi:362 */
			phandle = < 0x9 >;                   /* in zephyr\dts\riscv\espressif\esp32c5\esp32c5_common.dtsi:394 */
		};

		/* node '/soc/gpio@60091000' defined in zephyr\dts\riscv\espressif\esp32c5\esp32c5_common.dtsi:365 */
		gpio0: gpio@60091000 {
			compatible = "espressif,esp32-gpio"; /* in zephyr\dts\riscv\espressif\esp32c5\esp32c5_common.dtsi:366 */
			gpio-controller;                     /* in zephyr\dts\riscv\espressif\esp32c5\esp32c5_common.dtsi:367 */
			#gpio-cells = < 0x2 >;               /* in zephyr\dts\riscv\espressif\esp32c5\esp32c5_common.dtsi:368 */
			reg = < 0x60091000 0x1000 >;         /* in zephyr\dts\riscv\espressif\esp32c5\esp32c5_common.dtsi:369 */
			interrupts = < 0x1f 0x0 0x0 >;       /* in zephyr\dts\riscv\espressif\esp32c5\esp32c5_common.dtsi:370 */
			interrupt-parent = < &intc >;        /* in zephyr\dts\riscv\espressif\esp32c5\esp32c5_common.dtsi:371 */
			ngpios = < 0x1d >;                   /* in zephyr\dts\riscv\espressif\esp32c5\esp32c5_common.dtsi:372 */
			status = "okay";                     /* in zephyr\boards\seeed\xiao_esp32c5\xiao_esp32c5_hpcore.dts:57 */
			phandle = < 0x7 >;                   /* in zephyr\boards\seeed\xiao_esp32c5\xiao_esp32c5_hpcore.dts:75 */
		};

		/* node '/soc/i2c@60004000' defined in zephyr\dts\riscv\espressif\esp32c5\esp32c5_common.dtsi:375 */
		i2c0: xiao_i2c: i2c@60004000 {
			compatible = "espressif,esp32-i2c"; /* in zephyr\dts\riscv\espressif\esp32c5\esp32c5_common.dtsi:376 */
			#address-cells = < 0x1 >;           /* in zephyr\dts\riscv\espressif\esp32c5\esp32c5_common.dtsi:377 */
			#size-cells = < 0x0 >;              /* in zephyr\dts\riscv\espressif\esp32c5\esp32c5_common.dtsi:378 */
			reg = < 0x60004000 0x1000 >;        /* in zephyr\dts\riscv\espressif\esp32c5\esp32c5_common.dtsi:379 */
			interrupts = < 0x38 0x0 0x0 >;      /* in zephyr\dts\riscv\espressif\esp32c5\esp32c5_common.dtsi:380 */
			interrupt-parent = < &intc >;       /* in zephyr\dts\riscv\espressif\esp32c5\esp32c5_common.dtsi:381 */
			clocks = < &clock 0x68 >;           /* in zephyr\dts\riscv\espressif\esp32c5\esp32c5_common.dtsi:382 */
			status = "okay";                    /* in zephyr\boards\seeed\xiao_esp32c5\xiao_esp32c5_hpcore.dts:73 */
			clock-frequency = < 0x61a80 >;      /* in zephyr\boards\seeed\xiao_esp32c5\xiao_esp32c5_hpcore.dts:74 */
			scl-gpios = < &gpio0 0x18 0x6 >;    /* in zephyr\boards\seeed\xiao_esp32c5\xiao_esp32c5_hpcore.dts:75 */
			sda-gpios = < &gpio0 0x17 0x6 >;    /* in zephyr\boards\seeed\xiao_esp32c5\xiao_esp32c5_hpcore.dts:76 */
			pinctrl-0 = < &i2c0_default >;      /* in zephyr\boards\seeed\xiao_esp32c5\xiao_esp32c5_hpcore.dts:77 */
			pinctrl-names = "default";          /* in zephyr\boards\seeed\xiao_esp32c5\xiao_esp32c5_hpcore.dts:78 */
		};

		/* node '/soc/i2s@6000c000' defined in zephyr\dts\riscv\espressif\esp32c5\esp32c5_common.dtsi:386 */
		i2s: i2s@6000c000 {
			compatible = "espressif,esp32-i2s"; /* in zephyr\dts\riscv\espressif\esp32c5\esp32c5_common.dtsi:387 */
			#address-cells = < 0x1 >;           /* in zephyr\dts\riscv\espressif\esp32c5\esp32c5_common.dtsi:388 */
			#size-cells = < 0x0 >;              /* in zephyr\dts\riscv\espressif\esp32c5\esp32c5_common.dtsi:389 */
			reg = < 0x6000c000 0x1000 >;        /* in zephyr\dts\riscv\espressif\esp32c5\esp32c5_common.dtsi:390 */
			interrupts = < 0x2d 0x0 0x0 >;      /* in zephyr\dts\riscv\espressif\esp32c5\esp32c5_common.dtsi:391 */
			interrupt-parent = < &intc >;       /* in zephyr\dts\riscv\espressif\esp32c5\esp32c5_common.dtsi:392 */
			clocks = < &clock 0x69 >;           /* in zephyr\dts\riscv\espressif\esp32c5\esp32c5_common.dtsi:393 */
			dmas = < &dma 0x2 >,
			       < &dma 0x3 >;                /* in zephyr\dts\riscv\espressif\esp32c5\esp32c5_common.dtsi:394 */
			dma-names = "rx",
			            "tx";                   /* in zephyr\dts\riscv\espressif\esp32c5\esp32c5_common.dtsi:395 */
			unit = < 0x0 >;                     /* in zephyr\dts\riscv\espressif\esp32c5\esp32c5_common.dtsi:396 */
			status = "disabled";                /* in zephyr\dts\riscv\espressif\esp32c5\esp32c5_common.dtsi:397 */
		};

		/* node '/soc/uart@60000000' defined in zephyr\dts\riscv\espressif\esp32c5\esp32c5_common.dtsi:400 */
		uart0: xiao_serial: uart@60000000 {
			compatible = "espressif,esp32-uart"; /* in zephyr\dts\riscv\espressif\esp32c5\esp32c5_common.dtsi:401 */
			reg = < 0x60000000 0x1000 >;         /* in zephyr\dts\riscv\espressif\esp32c5\esp32c5_common.dtsi:402 */
			interrupts = < 0x2f 0x0 0x0 >;       /* in zephyr\dts\riscv\espressif\esp32c5\esp32c5_common.dtsi:404 */
			interrupt-parent = < &intc >;        /* in zephyr\dts\riscv\espressif\esp32c5\esp32c5_common.dtsi:405 */
			clocks = < &clock 0x65 >;            /* in zephyr\dts\riscv\espressif\esp32c5\esp32c5_common.dtsi:406 */
			status = "okay";                     /* in zephyr\boards\seeed\xiao_esp32c5\xiao_esp32c5_hpcore.dts:90 */
			current-speed = < 0x1c200 >;         /* in zephyr\boards\seeed\xiao_esp32c5\xiao_esp32c5_hpcore.dts:91 */
			pinctrl-0 = < &uart0_default >;      /* in zephyr\boards\seeed\xiao_esp32c5\xiao_esp32c5_hpcore.dts:92 */
			pinctrl-names = "default";           /* in zephyr\boards\seeed\xiao_esp32c5\xiao_esp32c5_hpcore.dts:93 */
		};

		/* node '/soc/uart@60001000' defined in zephyr\dts\riscv\espressif\esp32c5\esp32c5_common.dtsi:409 */
		uart1: uart@60001000 {
			compatible = "espressif,esp32-uart"; /* in zephyr\dts\riscv\espressif\esp32c5\esp32c5_common.dtsi:410 */
			reg = < 0x60001000 0x1000 >;         /* in zephyr\dts\riscv\espressif\esp32c5\esp32c5_common.dtsi:411 */
			status = "disabled";                 /* in zephyr\dts\riscv\espressif\esp32c5\esp32c5_common.dtsi:412 */
			interrupts = < 0x30 0x0 0x0 >;       /* in zephyr\dts\riscv\espressif\esp32c5\esp32c5_common.dtsi:413 */
			interrupt-parent = < &intc >;        /* in zephyr\dts\riscv\espressif\esp32c5\esp32c5_common.dtsi:414 */
			clocks = < &clock 0x66 >;            /* in zephyr\dts\riscv\espressif\esp32c5\esp32c5_common.dtsi:415 */
			current-speed = < 0x1c200 >;         /* in zephyr\dts\riscv\espressif\esp32c5\esp32c5_common.dtsi:416 */
		};

		/* node '/soc/uart@600b1400' defined in zephyr\dts\riscv\espressif\esp32c5\esp32c5_common.dtsi:419 */
		lp_uart: uart@600b1400 {
			compatible = "espressif,esp32-lpuart"; /* in zephyr\dts\riscv\espressif\esp32c5\esp32c5_common.dtsi:420 */
			reg = < 0x600b1400 0x1000 >;           /* in zephyr\dts\riscv\espressif\esp32c5\esp32c5_common.dtsi:421 */
			interrupts = < 0x10 0x0 0x0 >;         /* in zephyr\dts\riscv\espressif\esp32c5\esp32c5_common.dtsi:422 */
			interrupt-parent = < &intc >;          /* in zephyr\dts\riscv\espressif\esp32c5\esp32c5_common.dtsi:423 */
			tx-pin = < 0x5 >;                      /* in zephyr\dts\riscv\espressif\esp32c5\esp32c5_common.dtsi:424 */
			rx-pin = < 0x4 >;                      /* in zephyr\dts\riscv\espressif\esp32c5\esp32c5_common.dtsi:425 */
			rts-pin = < 0x2 >;                     /* in zephyr\dts\riscv\espressif\esp32c5\esp32c5_common.dtsi:426 */
			cts-pin = < 0x3 >;                     /* in zephyr\dts\riscv\espressif\esp32c5\esp32c5_common.dtsi:427 */
			status = "disabled";                   /* in zephyr\dts\riscv\espressif\esp32c5\esp32c5_common.dtsi:428 */
			current-speed = < 0x1c200 >;           /* in zephyr\dts\riscv\espressif\esp32c5\esp32c5_common.dtsi:429 */
		};

		/* node '/soc/uart@6000f000' defined in zephyr\dts\riscv\espressif\esp32c5\esp32c5_common.dtsi:432 */
		usb_serial: uart@6000f000 {
			compatible = "espressif,esp32-usb-serial"; /* in zephyr\dts\riscv\espressif\esp32c5\esp32c5_common.dtsi:433 */
			reg = < 0x6000f000 0x1000 >;               /* in zephyr\dts\riscv\espressif\esp32c5\esp32c5_common.dtsi:434 */
			interrupts = < 0x36 0x0 0x0 >;             /* in zephyr\dts\riscv\espressif\esp32c5\esp32c5_common.dtsi:436 */
			interrupt-parent = < &intc >;              /* in zephyr\dts\riscv\espressif\esp32c5\esp32c5_common.dtsi:437 */
			clocks = < &clock 0x67 >;                  /* in zephyr\dts\riscv\espressif\esp32c5\esp32c5_common.dtsi:438 */
			status = "okay";                           /* in zephyr\boards\seeed\xiao_esp32c5\xiao_esp32c5_hpcore.dts:65 */
		};

		/* node '/soc/ledc@60007000' defined in zephyr\dts\riscv\espressif\esp32c5\esp32c5_common.dtsi:441 */
		ledc0: ledc@60007000 {
			compatible = "espressif,esp32-ledc"; /* in zephyr\dts\riscv\espressif\esp32c5\esp32c5_common.dtsi:442 */
			pwm-controller;                      /* in zephyr\dts\riscv\espressif\esp32c5\esp32c5_common.dtsi:443 */
			#pwm-cells = < 0x3 >;                /* in zephyr\dts\riscv\espressif\esp32c5\esp32c5_common.dtsi:444 */
			reg = < 0x60007000 0x1000 >;         /* in zephyr\dts\riscv\espressif\esp32c5\esp32c5_common.dtsi:445 */
			clocks = < &clock 0x64 >;            /* in zephyr\dts\riscv\espressif\esp32c5\esp32c5_common.dtsi:446 */
			status = "disabled";                 /* in zephyr\dts\riscv\espressif\esp32c5\esp32c5_common.dtsi:447 */
		};

		/* node '/soc/mcpwm@60014000' defined in zephyr\dts\riscv\espressif\esp32c5\esp32c5_common.dtsi:450 */
		mcpwm0: mcpwm@60014000 {
			compatible = "espressif,esp32-mcpwm"; /* in zephyr\dts\riscv\espressif\esp32c5\esp32c5_common.dtsi:451 */
			reg = < 0x60014000 0x1000 >;          /* in zephyr\dts\riscv\espressif\esp32c5\esp32c5_common.dtsi:452 */
			interrupts = < 0x41 0x0 0x0 >;        /* in zephyr\dts\riscv\espressif\esp32c5\esp32c5_common.dtsi:453 */
			interrupt-parent = < &intc >;         /* in zephyr\dts\riscv\espressif\esp32c5\esp32c5_common.dtsi:454 */
			clocks = < &clock 0x72 >;             /* in zephyr\dts\riscv\espressif\esp32c5\esp32c5_common.dtsi:455 */
			#pwm-cells = < 0x3 >;                 /* in zephyr\dts\riscv\espressif\esp32c5\esp32c5_common.dtsi:456 */
			status = "disabled";                  /* in zephyr\dts\riscv\espressif\esp32c5\esp32c5_common.dtsi:457 */
		};

		/* node '/soc/pcnt@60012000' defined in zephyr\dts\riscv\espressif\esp32c5\esp32c5_common.dtsi:460 */
		pcnt: pcnt@60012000 {
			compatible = "espressif,esp32-pcnt"; /* in zephyr\dts\riscv\espressif\esp32c5\esp32c5_common.dtsi:461 */
			reg = < 0x60012000 0x1000 >;         /* in zephyr\dts\riscv\espressif\esp32c5\esp32c5_common.dtsi:462 */
			interrupts = < 0x42 0x0 0x0 >;       /* in zephyr\dts\riscv\espressif\esp32c5\esp32c5_common.dtsi:463 */
			interrupt-parent = < &intc >;        /* in zephyr\dts\riscv\espressif\esp32c5\esp32c5_common.dtsi:464 */
			clocks = < &clock 0x6b >;            /* in zephyr\dts\riscv\espressif\esp32c5\esp32c5_common.dtsi:465 */
			status = "disabled";                 /* in zephyr\dts\riscv\espressif\esp32c5\esp32c5_common.dtsi:466 */
		};

		/* node '/soc/sha@60089000' defined in zephyr\dts\riscv\espressif\esp32c5\esp32c5_common.dtsi:469 */
		sha: sha@60089000 {
			compatible = "espressif,esp32-sha"; /* in zephyr\dts\riscv\espressif\esp32c5\esp32c5_common.dtsi:470 */
			reg = < 0x60089000 0x100 >;         /* in zephyr\dts\riscv\espressif\esp32c5\esp32c5_common.dtsi:471 */
			clocks = < &clock 0x79 >;           /* in zephyr\dts\riscv\espressif\esp32c5\esp32c5_common.dtsi:472 */
			status = "okay";                    /* in zephyr\dts\riscv\espressif\esp32c5\esp32c5_common.dtsi:473 */
		};

		/* node '/soc/aes@60088000' defined in zephyr\dts\riscv\espressif\esp32c5\esp32c5_common.dtsi:476 */
		aes: aes@60088000 {
			compatible = "espressif,esp32-aes"; /* in zephyr\dts\riscv\espressif\esp32c5\esp32c5_common.dtsi:477 */
			reg = < 0x60088000 0x1000 >;        /* in zephyr\dts\riscv\espressif\esp32c5\esp32c5_common.dtsi:478 */
			clocks = < &clock 0x78 >;           /* in zephyr\dts\riscv\espressif\esp32c5\esp32c5_common.dtsi:479 */
			status = "okay";                    /* in zephyr\dts\riscv\espressif\esp32c5\esp32c5_common.dtsi:480 */
		};
	};

	/* node '/connector' defined in zephyr\boards\seeed\xiao_esp32c5\seeed_xiao_connector.dtsi:7 */
	xiao_d: connector {
		compatible = "seeed,xiao-gpio";            /* in zephyr\boards\seeed\xiao_esp32c5\seeed_xiao_connector.dtsi:8 */
		#gpio-cells = < 0x2 >;                     /* in zephyr\boards\seeed\xiao_esp32c5\seeed_xiao_connector.dtsi:9 */
		gpio-map-mask = < 0xffffffff 0xffffffc0 >; /* in zephyr\boards\seeed\xiao_esp32c5\seeed_xiao_connector.dtsi:10 */
		gpio-map-pass-thru = < 0x0 0x3f >;         /* in zephyr\boards\seeed\xiao_esp32c5\seeed_xiao_connector.dtsi:11 */
		gpio-map = < 0x0 0x0 &gpio0 0x1 0x0 >,
		           < 0x1 0x0 &gpio0 0x0 0x0 >,
		           < 0x2 0x0 &gpio0 0x19 0x0 >,
		           < 0x3 0x0 &gpio0 0x7 0x0 >,
		           < 0x4 0x0 &gpio0 0x17 0x0 >,
		           < 0x5 0x0 &gpio0 0x18 0x0 >,
		           < 0x6 0x0 &gpio0 0xb 0x0 >,
		           < 0x7 0x0 &gpio0 0xc 0x0 >,
		           < 0x8 0x0 &gpio0 0x8 0x0 >,
		           < 0x9 0x0 &gpio0 0x9 0x0 >,
		           < 0xa 0x0 &gpio0 0xa 0x0 >;     /* in zephyr\boards\seeed\xiao_esp32c5\seeed_xiao_connector.dtsi:12 */
	};

	/* node '/leds' defined in zephyr\boards\seeed\xiao_esp32c5\xiao_esp32c5_hpcore.dts:27 */
	leds: leds {
		compatible = "gpio-leds"; /* in zephyr\boards\seeed\xiao_esp32c5\xiao_esp32c5_hpcore.dts:28 */

		/* node '/leds/led_0' defined in zephyr\boards\seeed\xiao_esp32c5\xiao_esp32c5_hpcore.dts:30 */
		yellow_led: led_0 {
			gpios = < &gpio0 0x1b 0x1 >; /* in zephyr\boards\seeed\xiao_esp32c5\xiao_esp32c5_hpcore.dts:31 */
			label = "User LED";          /* in zephyr\boards\seeed\xiao_esp32c5\xiao_esp32c5_hpcore.dts:32 */
		};
	};

	/* node '/gpio_keys' defined in zephyr\boards\seeed\xiao_esp32c5\xiao_esp32c5_hpcore.dts:41 */
	gpio_keys {
		compatible = "gpio-keys"; /* in zephyr\boards\seeed\xiao_esp32c5\xiao_esp32c5_hpcore.dts:42 */

		/* node '/gpio_keys/button' defined in zephyr\boards\seeed\xiao_esp32c5\xiao_esp32c5_hpcore.dts:44 */
		boot_button: button {
			label = "Boot Button";        /* in zephyr\boards\seeed\xiao_esp32c5\xiao_esp32c5_hpcore.dts:45 */
			gpios = < &gpio0 0x1c 0x11 >; /* in zephyr\boards\seeed\xiao_esp32c5\xiao_esp32c5_hpcore.dts:46 */
			zephyr,code = < 0xb >;        /* in zephyr\boards\seeed\xiao_esp32c5\xiao_esp32c5_hpcore.dts:47 */
		};
	};
};
